VERSION ""

NS_ :

BS_:

BU_: CCU EDC ADAS
VAL_TABLE_ vtbSensorReqCause 15 "SNA" 2 "by Request 2" 1 "by Request 1" 0 "normal cycle" ;
VAL_TABLE_ vtbErrorDescription 255 "ERROR" ;

BO_ 2015 msg_broad_diag_request: 8 CCU
 SG_ sig_broad_diag_request : 0|64@1+ (1,0) [0|0] ""  ADAS,EDC

BO_ 1898 msg_edc_diag_response: 8 EDC
 SG_ sig_edc_diag_response : 0|64@1+ (1,0) [0|0] ""  CCU

BO_ 1890 msg_edc_diag_request: 8 CCU
 SG_ sig_edc_diag_request : 0|64@1+ (1,0) [0|0] ""  EDC

BO_ 1897 msg_adas_diag_response: 8 ADAS
 SG_ sig_adas_diag_response : 0|64@1+ (1,0) [0|0] ""  CCU

BO_ 1889 msg_adas_diag_request: 8 CCU
 SG_ sig_adas_diag_request : 0|64@1+ (1,0) [0|0] ""  ADAS

BO_ 1061 msg_fconsole_cruise: 1 CCU
 SG_ sig_cruise_state : 0|1@1+ (1,0) [0|1] ""  ADAS

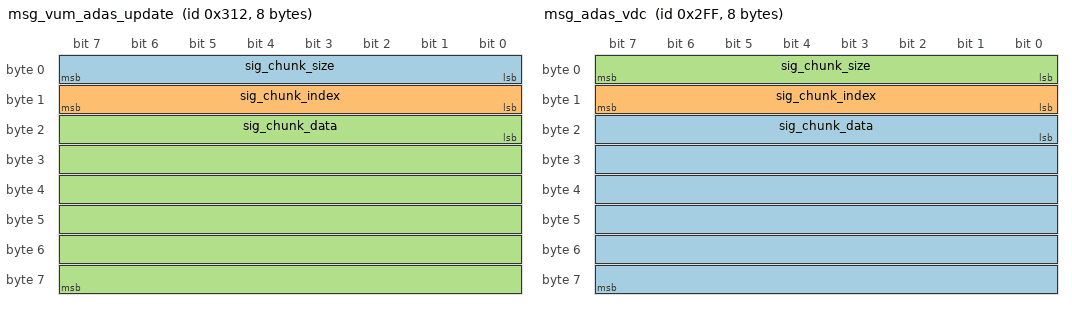
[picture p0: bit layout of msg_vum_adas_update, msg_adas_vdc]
BO_ 786 msg_vum_adas_update: 8 CCU
 SG_ sig_chunk_size : 0|8@1+ (1,0) [0|255] ""  ADAS
 SG_ sig_chunk_index : 8|8@1+ (1,0) [0|255] ""  ADAS
 SG_ sig_chunk_data : 16|48@1+ (1,0) [0|281474976710655] ""  ADAS

BO_ 785 msg_vum_check_update: 2 CCU
 SG_ sig_check_status : 8|4@1+ (1,0) [0|15] ""  ADAS
 SG_ sig_target_ecu : 0|8@1+ (1,0) [0|255] ""  ADAS

BO_ 1073 msg_mfsw_status: 1 CCU
 SG_ sig_cruise_state : 0|1@1+ (1,0) [0|1] ""  ADAS

BO_ 289 msg_rmdps_steer_angle: 2 CCU
 SG_ sig_steer_angle : 0|16@1- (1,0) [-32768|32767] ""  ADAS

BO_ 767 msg_adas_vdc: 8 EDC
 SG_ sig_chunk_data : 16|48@1+ (1,0) [0|281474976710655] ""  CCU
 SG_ sig_chunk_index : 8|8@1+ (1,0) [0|255] ""  CCU
 SG_ sig_chunk_size : 0|8@1+ (1,0) [0|255] ""  CCU

BO_ 531 msg_adas_can_vum: 1 ADAS
 SG_ sig_adas_can_vum : 0|1@1+ (1,0) [0|1] ""  EDC,CCU

BO_ 543 msg_adas_alive: 1 ADAS
 SG_ sig_adas_alive : 0|1@1+ (1,0) [0|1] ""  EDC

BO_ 542 msg_adas_edc: 4 ADAS
 SG_ sig_adas_dtc : 0|32@1+ (1,0) [0|4294967295] ""  EDC

BO_ 530 msg_adas_rmdps: 2 ADAS
 SG_ sig_adas_steer_angle : 0|16@1- (1,0) [-32768|32767] ""  EDC,CCU

BO_ 529 msg_adas_ieb: 1 ADAS
 SG_ sig_adas_ieb_cmd : 0|1@1+ (1,0) [0|1] ""  EDC,CCU

BA_DEF_  "DatabaseVersion" STRING ;
BA_DEF_  "Manufacturer" STRING ;
BA_DEF_ BU_  "NodeLayerModules" STRING ;
BA_DEF_  "BusType" STRING ;
BA_DEF_ SG_  "GenSigSendType" ENUM  "Cyclic","OnWrite","OnWriteWithRepetition","OnChange","OnChangeWithRepetition","IfActive","IfActiveWithRepetition","NoSigSendType","NotUsed","NotUsed","NotUsed","NotUsed","NotUsed";
BA_DEF_ BO_  "GenMsgSendType" ENUM  "Cyclic","NotUsed","NotUsed","NotUsed","NotUsed","Cyclic","NotUsed","IfActive","NoMsgSendType","NotUsed","vector_leerstring";
BA_DEF_ BO_  "GenMsgCycleTime" INT 0 50000;
BA_DEF_ BO_  "GenMsgCycleTimeFast" INT 0 50000;
BA_DEF_ BO_  "GenMsgILSupport" ENUM  "No","Yes";
BA_DEF_DEF_  "DatabaseVersion" "";
BA_DEF_DEF_  "Manufacturer" "Vector";
BA_DEF_DEF_  "NodeLayerModules" "CANoeILNLVector.dll";
BA_DEF_DEF_  "BusType" "CAN";
BA_DEF_DEF_  "GenSigSendType" "Cyclic";
BA_DEF_DEF_  "GenMsgSendType" "NoMsgSendType";
BA_DEF_DEF_  "GenMsgCycleTime" 200;
BA_DEF_DEF_  "GenMsgCycleTimeFast" 20;
BA_DEF_DEF_  "GenMsgILSupport" "Yes";
BA_ "DatabaseVersion" "1.1";
